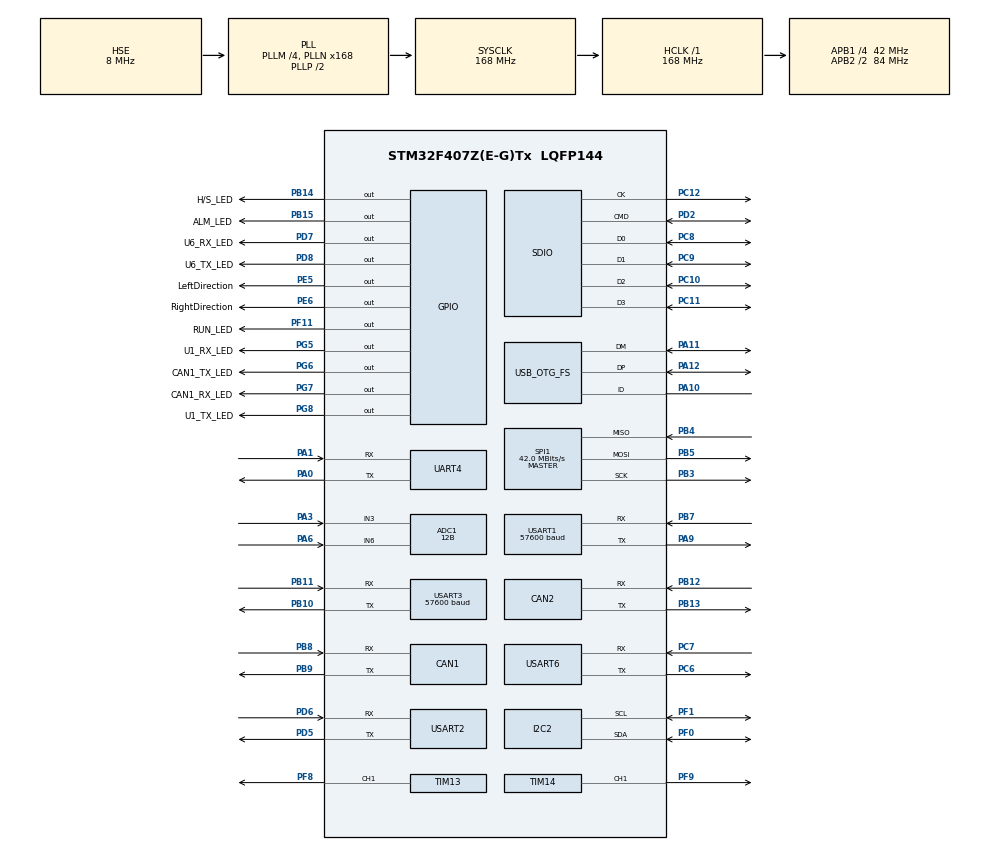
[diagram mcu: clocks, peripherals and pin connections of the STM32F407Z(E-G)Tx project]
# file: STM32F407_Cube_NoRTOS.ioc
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ADC1.Channel-0\#ChannelRegularConversion=ADC_CHANNEL_3
ADC1.ClockPrescaler=ADC_CLOCK_SYNC_PCLK_DIV4
ADC1.ContinuousConvMode=DISABLE
ADC1.DMAContinuousRequests=DISABLE
ADC1.DataAlign=ADC_DATAALIGN_RIGHT
ADC1.DiscontinuousConvMode=DISABLE
ADC1.EOCSelection=ADC_EOC_SINGLE_CONV
ADC1.EnableAnalogWatchDog=false
ADC1.ExternalTrigConv=ADC_SOFTWARE_START
ADC1.ExternalTrigConvEdge=ADC_EXTERNALTRIGCONVEDGE_NONE
ADC1.InjNumberOfConversion=0
ADC1.NbrOfConversion=1
ADC1.NbrOfConversionFlag=1
ADC1.Rank-0\#ChannelRegularConversion=1
ADC1.Resolution=ADC_RESOLUTION_12B
ADC1.SamplingTime-0\#ChannelRegularConversion=ADC_SAMPLETIME_3CYCLES
ADC1.ScanConvMode=DISABLE
ADC1.master=1
CAN1.BS1=CAN_BS1_1TQ
CAN1.BS2=CAN_BS2_1TQ
CAN1.CalculateTimeBit=1142
CAN1.CalculateTimeQuantum=380.95238095238096
CAN2.BS1=CAN_BS1_1TQ
CAN2.BS2=CAN_BS2_1TQ
CAN2.CalculateTimeBit=1142
CAN2.CalculateTimeQuantum=380.95238095238096
Mcu.Family=STM32F4
Mcu.Name=STM32F407Z(E-G)Tx
Mcu.Package=LQFP144
NVIC.PriorityGroup=NVIC_PRIORITYGROUP_4
NVIC.TIM6_DAC_IRQn=true\:0\:0\:false\:false\:true\:true
NVIC.TIM7_IRQn=true\:0\:0\:false\:false\:true\:true
NVIC.USART3_IRQn=true\:5\:0\:true\:false\:true\:true
PA0-WKUP.Mode=Multiprocessor_communication
PA0-WKUP.Signal=UART4_TX
PA1.Mode=Multiprocessor_communication
PA1.Signal=UART4_RX
PA10.Mode=OTG/Dual_Role_Device
PA10.Signal=USB_OTG_FS_ID
PA11.Mode=OTG/Dual_Role_Device
PA11.Signal=USB_OTG_FS_DM
PA12.Mode=OTG/Dual_Role_Device
PA12.Signal=USB_OTG_FS_DP
PA13.Signal=SYS_JTMS-SWDIO
PA14.Signal=SYS_JTCK-SWCLK
PA15.Signal=SPI1_NSS
PA3.Signal=ADCx_IN3
PA6.Signal=ADCx_IN6
PA9.Mode=Multiprocessor_communication
PA9.Signal=USART1_TX
PB10.Mode=Multiprocessor_communication
PB10.Signal=USART3_TX
PB11.Mode=Multiprocessor_communication
PB11.Signal=USART3_RX
PB12.Mode=Slave
PB12.Signal=CAN2_RX
PB13.Mode=Slave
PB13.Signal=CAN2_TX
PB14.GPIO_Label=H/S_LED
PB14.PinState=GPIO_PIN_SET
PB14.Signal=GPIO_Output
PB15.GPIO_Label=ALM_LED
PB15.PinState=GPIO_PIN_SET
PB15.Signal=GPIO_Output
PB3.Mode=Full_Duplex_Master
PB3.Signal=SPI1_SCK
PB4.Mode=Full_Duplex_Master
PB4.Signal=SPI1_MISO
PB5.Mode=Full_Duplex_Master
PB5.Signal=SPI1_MOSI
PB7.Mode=Multiprocessor_communication
PB7.Signal=USART1_RX
PB8.Mode=Master
PB8.Signal=CAN1_RX
PB9.Mode=Master
PB9.Signal=CAN1_TX
PC10.Mode=SD_4_bits_Wide_bus
PC10.Signal=SDIO_D2
PC11.Mode=SD_4_bits_Wide_bus
PC11.Signal=SDIO_D3
PC12.Mode=SD_4_bits_Wide_bus
PC12.Signal=SDIO_CK
PC6.Mode=Multiprocessor_communication
PC6.Signal=USART6_TX
PC7.Mode=Multiprocessor_communication
PC7.Signal=USART6_RX
PC8.Mode=SD_4_bits_Wide_bus
PC8.Signal=SDIO_D0
PC9.Mode=SD_4_bits_Wide_bus
PC9.Signal=SDIO_D1
PD2.Mode=SD_4_bits_Wide_bus
PD2.Signal=SDIO_CMD
PD5.Mode=Multiprocessor_communication
PD5.Signal=USART2_TX
PD6.Mode=Multiprocessor_communication
PD6.Signal=USART2_RX
PD7.GPIO_Label=U6_RX_LED
PD7.PinState=GPIO_PIN_SET
PD7.Signal=GPIO_Output
PD8.GPIO_Label=U6_TX_LED
PD8.PinState=GPIO_PIN_SET
PD8.Signal=GPIO_Output
PE5.GPIO_Label=LeftDirection
PE5.PinState=GPIO_PIN_SET
PE5.Signal=GPIO_Output
PE6.GPIO_Label=RightDirection
PE6.PinState=GPIO_PIN_SET
PE6.Signal=GPIO_Output
PF0.Mode=I2C
PF0.Signal=I2C2_SDA
PF1.Mode=I2C
PF1.Signal=I2C2_SCL
PF11.GPIO_Label=RUN_LED
PF11.PinState=GPIO_PIN_SET
PF11.Signal=GPIO_Output
PF6.Signal=S_TIM10_CH1
PF8.Signal=S_TIM13_CH1
PF9.Signal=S_TIM14_CH1
PG5.GPIO_Label=U1_RX_LED
PG5.PinState=GPIO_PIN_SET
PG5.Signal=GPIO_Output
PG6.GPIO_Label=CAN1_TX_LED
PG6.PinState=GPIO_PIN_SET
PG6.Signal=GPIO_Output
PG7.GPIO_Label=CAN1_RX_LED
PG7.PinState=GPIO_PIN_SET
PG7.Signal=GPIO_Output
PG8.GPIO_Label=U1_TX_LED
PG8.PinState=GPIO_PIN_SET
PG8.Signal=GPIO_Output
PH0-OSC_IN.Mode=HSE-External-Oscillator
PH0-OSC_IN.Signal=RCC_OSC_IN
PH1-OSC_OUT.Mode=HSE-External-Oscillator
PH1-OSC_OUT.Signal=RCC_OSC_OUT
ProjectManager.HeapSize=0x200
ProjectManager.StackSize=0x400
ProjectManager.TargetToolchain=MDK-ARM V5
RCC.48MHZClocksFreq_Value=48000000
RCC.AHBFreq_Value=168000000
RCC.APB1CLKDivider=RCC_HCLK_DIV4
RCC.APB1Freq_Value=42000000
RCC.APB1TimFreq_Value=84000000
RCC.APB2CLKDivider=RCC_HCLK_DIV2
RCC.APB2Freq_Value=84000000
RCC.APB2TimFreq_Value=168000000
RCC.CortexFreq_Value=168000000
RCC.HCLKFreq_Value=168000000
RCC.HSE_VALUE=8000000
RCC.HSI_VALUE=16000000
RCC.LSE_VALUE=32768
RCC.PLLM=4
RCC.PLLN=168
RCC.PLLQ=7
RCC.SYSCLKFreq_VALUE=168000000
RCC.SYSCLKSource=RCC_SYSCLKSOURCE_PLLCLK
RCC.VCOOutputFreq_Value=336000000
SH.ADCx_IN3.0=ADC1_IN3,IN3
SH.ADCx_IN6.0=ADC1_IN6,IN6
SH.S_TIM10_CH1.0=TIM10_CH1
SH.S_TIM13_CH1.0=TIM13_CH1,PWM Generation1 CH1
SH.S_TIM14_CH1.0=TIM14_CH1,PWM Generation1 CH1
SPI1.BaudRatePrescaler=SPI_BAUDRATEPRESCALER_2
SPI1.CalculateBaudRate=42.0 MBits/s
SPI1.Direction=SPI_DIRECTION_2LINES
SPI1.Mode=SPI_MODE_MASTER
SPI1.VirtualType=VM_MASTER
TIM13.Channel=TIM_CHANNEL_1
TIM13.Period=500
TIM13.Prescaler=83
TIM13.Pulse=100
TIM14.Channel=TIM_CHANNEL_1
TIM14.Period=500
TIM14.Prescaler=83
TIM14.Pulse=100
TIM6.Period=500
TIM6.Prescaler=83
TIM7.Period=5000
TIM7.Prescaler=8399
UART4.VirtualMode=Asynchronous
USART1.BaudRate=57600
USART1.VirtualMode=VM_ASYNC
USART2.VirtualMode=VM_ASYNC
USART3.BaudRate=57600
USART3.VirtualMode=VM_ASYNC
USART6.VirtualMode=VM_ASYNC
VP_TIM13_VS_ClockSourceINT.Mode=Enable_Timer
VP_TIM14_VS_ClockSourceINT.Mode=Enable_Timer
VP_TIM6_VS_ClockSourceINT.Mode=Enable_Timer
VP_TIM7_VS_ClockSourceINT.Mode=Enable_Timer
board=STM32F407_Cube_NoRTOS

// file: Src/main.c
/**
  ******************************************************************************
  * File Name          : main.c
  * Description        : Main program body
  ******************************************************************************
  *
  * COPYRIGHT(c) 2017 STMicroelectronics
  *
  * Redistribution and use in source and binary forms, with or without modification,
  * are permitted provided that the following conditions are met:
  *   1. Redistributions of source code must retain the above copyright notice,
  *      this list of conditions and the following disclaimer.
  *   2. Redistributions in binary form must reproduce the above copyright notice,
  *      this list of conditions and the following disclaimer in the documentation
  *      and/or other materials provided with the distribution.
  *   3. Neither the name of STMicroelectronics nor the names of its contributors
  *      may be used to endorse or promote products derived from this software
  *      without specific prior written permission.
  *
  * THIS SOFTWARE IS PROVIDED BY THE COPYRIGHT HOLDERS AND CONTRIBUTORS "AS IS"
  * AND ANY EXPRESS OR IMPLIED WARRANTIES, INCLUDING, BUT NOT LIMITED TO, THE
  * IMPLIED WARRANTIES OF MERCHANTABILITY AND FITNESS FOR A PARTICULAR PURPOSE ARE
  * DISCLAIMED. IN NO EVENT SHALL THE COPYRIGHT HOLDER OR CONTRIBUTORS BE LIABLE
  * FOR ANY DIRECT, INDIRECT, INCIDENTAL, SPECIAL, EXEMPLARY, OR CONSEQUENTIAL
  * DAMAGES (INCLUDING, BUT NOT LIMITED TO, PROCUREMENT OF SUBSTITUTE GOODS OR
  * SERVICES; LOSS OF USE, DATA, OR PROFITS; OR BUSINESS INTERRUPTION) HOWEVER
  * CAUSED AND ON ANY THEORY OF LIABILITY, WHETHER IN CONTRACT, STRICT LIABILITY,
  * OR TORT (INCLUDING NEGLIGENCE OR OTHERWISE) ARISING IN ANY WAY OUT OF THE USE
  * OF THIS SOFTWARE, EVEN IF ADVISED OF THE POSSIBILITY OF SUCH DAMAGE.
  *
  ******************************************************************************
  */
#include "main.h"
#include "stm32f4xx_hal.h"
#include "adc.h"
#include "can.h"
#include "i2c.h"
#include "sdio.h"
#include "spi.h"
#include "tim.h"
#include "usart.h"
#include "usb_otg.h"
#include "gpio.h"

/* USER CODE BEGIN Includes */
#include "car.h"
/* USER CODE END Includes */

/* USER CODE BEGIN PV */
/* Private variables ---------------------------------------------------------*/

/* USER CODE END PV */

void SystemClock_Config(void);
void Error_Handler(void);

/* USER CODE BEGIN PFP */
/* Private function prototypes -----------------------------------------------*/

/* USER CODE END PFP */

int main(void)
{

  /* MCU Configuration----------------------------------------------------------*/

  /* Reset of all peripherals, Initializes the Flash interface and the Systick. */
  HAL_Init();

  /* Configure the system clock */
  SystemClock_Config();

  /* Initialize all configured peripherals */
  MX_GPIO_Init();
  MX_CAN1_Init();
  MX_CAN2_Init();
  MX_USART3_UART_Init();
  MX_TIM13_Init();
  MX_TIM14_Init();
  MX_SPI1_Init();
  MX_USART2_UART_Init();
  MX_USART6_UART_Init();
  MX_UART4_Init();
  MX_ADC1_Init();
  MX_USB_OTG_FS_USB_Init();
  MX_TIM6_Init();
  MX_TIM7_Init();
  MX_I2C2_Init();
  MX_USART1_UART_Init();
  MX_SDIO_SD_Init();

  /* Infinite loop */
  /* USER CODE BEGIN WHILE */

	if(HAL_UART_Receive_IT(&huart3,&serial_rec,1)!=HAL_OK)	Error_Handler();
	if(HAL_TIM_Base_Start_IT(&htim6) != HAL_OK)							Error_Handler();
	if(HAL_TIM_Base_Start_IT(&htim7) != HAL_OK)							Error_Handler();

	if(HAL_TIM_PWM_Start(&htim13,TIM_CHANNEL_1) != HAL_OK)							Error_Handler();
	if(HAL_TIM_PWM_Start(&htim14,TIM_CHANNEL_1) != HAL_OK)							Error_Handler();

  while (1)
  {
  /* USER CODE END WHILE */

  /* USER CODE BEGIN 3 */
		CarMainFunction();
  }
  /* USER CODE END 3 */

}

/** System Clock Configuration
*/
void SystemClock_Config(void)
{

  RCC_OscInitTypeDef RCC_OscInitStruct;
  RCC_ClkInitTypeDef RCC_ClkInitStruct;

    /**Configure the main internal regulator output voltage
    */
  __HAL_RCC_PWR_CLK_ENABLE();

  __HAL_PWR_VOLTAGESCALING_CONFIG(PWR_REGULATOR_VOLTAGE_SCALE1);

    /**Initializes the CPU, AHB and APB busses clocks
    */
  RCC_OscInitStruct.OscillatorType = RCC_OSCILLATORTYPE_HSE;
  RCC_OscInitStruct.HSEState = RCC_HSE_ON;
  RCC_OscInitStruct.PLL.PLLState = RCC_PLL_ON;
  RCC_OscInitStruct.PLL.PLLSource = RCC_PLLSOURCE_HSE;
  RCC_OscInitStruct.PLL.PLLM = 4;
  RCC_OscInitStruct.PLL.PLLN = 168;
  RCC_OscInitStruct.PLL.PLLP = RCC_PLLP_DIV2;
  RCC_OscInitStruct.PLL.PLLQ = 7;
  if (HAL_RCC_OscConfig(&RCC_OscInitStruct) != HAL_OK)
  {
    Error_Handler();
  }

    /**Initializes the CPU, AHB and APB busses clocks
    */
  RCC_ClkInitStruct.ClockType = RCC_CLOCKTYPE_HCLK|RCC_CLOCKTYPE_SYSCLK
                              |RCC_CLOCKTYPE_PCLK1|RCC_CLOCKTYPE_PCLK2;
  RCC_ClkInitStruct.SYSCLKSource = RCC_SYSCLKSOURCE_PLLCLK;
  RCC_ClkInitStruct.AHBCLKDivider = RCC_SYSCLK_DIV1;
  RCC_ClkInitStruct.APB1CLKDivider = RCC_HCLK_DIV4;
  RCC_ClkInitStruct.APB2CLKDivider = RCC_HCLK_DIV2;

  if (HAL_RCC_ClockConfig(&RCC_ClkInitStruct, FLASH_LATENCY_5) != HAL_OK)
  {
    Error_Handler();
  }

    /**Configure the Systick interrupt time
    */
  HAL_SYSTICK_Config(HAL_RCC_GetHCLKFreq()/1000);

    /**Configure the Systick
    */
  HAL_SYSTICK_CLKSourceConfig(SYSTICK_CLKSOURCE_HCLK);

  /* SysTick_IRQn interrupt configuration */
  HAL_NVIC_SetPriority(SysTick_IRQn, 0, 0);
}

void Error_Handler(void)
{
  while(1)
  {
  }
}

/************************ (C) COPYRIGHT STMicroelectronics *****END OF FILE****/
